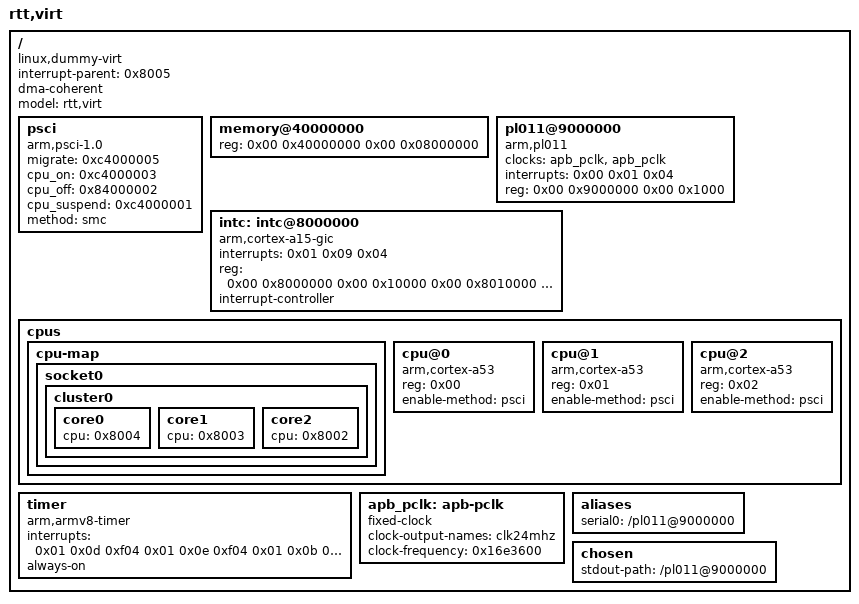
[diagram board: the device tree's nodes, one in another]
/dts-v1/;

/ {
    interrupt-parent = <0x8005>;
    dma-coherent;
    model = "rtt,virt";
    compatible = "linux,dummy-virt";
    #address-cells = <0x02>;
    #size-cells = <0x02>;

    psci {
        migrate = <0xc4000005>;
        cpu_on = <0xc4000003>;
        cpu_off = <0x84000002>;
        cpu_suspend = <0xc4000001>;
        method = "smc";
        compatible = "arm,psci-1.0", "arm,psci-0.2", "arm,psci";
    };

    memory@40000000 {
        device_type = "memory";
        reg = <0x00 0x40000000 0x00 0x08000000>;
    };

    pl011@9000000 {
        clock-names = "uartclk", "apb_pclk";
        clocks = <&apb_pclk &apb_pclk>;
        interrupts = <0x00 0x01 0x04>;
        reg = <0x00 0x9000000 0x00 0x1000>;
        compatible = "arm,pl011", "arm,primecell";
    };

    intc: intc@8000000 {
        phandle = <0x8005>;
        interrupts = <0x01 0x09 0x04>;
        reg = <0x00 0x8000000 0x00 0x10000 0x00 0x8010000 0x00 0x10000 0x00 0x8030000 0x00 0x10000 0x00 0x8040000 0x00 0x10000>;
        compatible = "arm,cortex-a15-gic";
        ranges;
        #size-cells = <0x02>;
        #address-cells = <0x02>;
        interrupt-controller;
        #interrupt-cells = <0x03>;
    };

    cpus {
        #size-cells = <0x00>;
        #address-cells = <0x01>;

        cpu-map {
            socket0 {
                cluster0 {
                    core0 { cpu = <0x8004>; };
                    core1 { cpu = <0x8003>; };
                    core2 { cpu = <0x8002>; };
                };
            };
        };

        cpu@0 {
            phandle = <0x8004>;
            reg = <0x00>;
            enable-method = "psci";
            compatible = "arm,cortex-a53";
            device_type = "cpu";
        };

        cpu@1 {
            phandle = <0x8003>;
            reg = <0x01>;
            enable-method = "psci";
            compatible = "arm,cortex-a53";
            device_type = "cpu";
        };

        cpu@2 {
            phandle = <0x8002>;
            reg = <0x02>;
            enable-method = "psci";
            compatible = "arm,cortex-a53";
            device_type = "cpu";
        };
    };

    timer {
        interrupts = <0x01 0x0d 0xf04 0x01 0x0e 0xf04 0x01 0x0b 0xf04 0x01 0x0a 0xf04>;
        always-on;
        compatible = "arm,armv8-timer", "arm,armv7-timer";
    };

    apb_pclk: apb-pclk {
        clock-output-names = "clk24mhz";
        clock-frequency = <0x16e3600>;
        #clock-cells = <0x00>;
        compatible = "fixed-clock";
    };

    aliases {
        serial0 = "/pl011@9000000";
    };

    chosen {
        stdout-path = "/pl011@9000000";
    };
};
